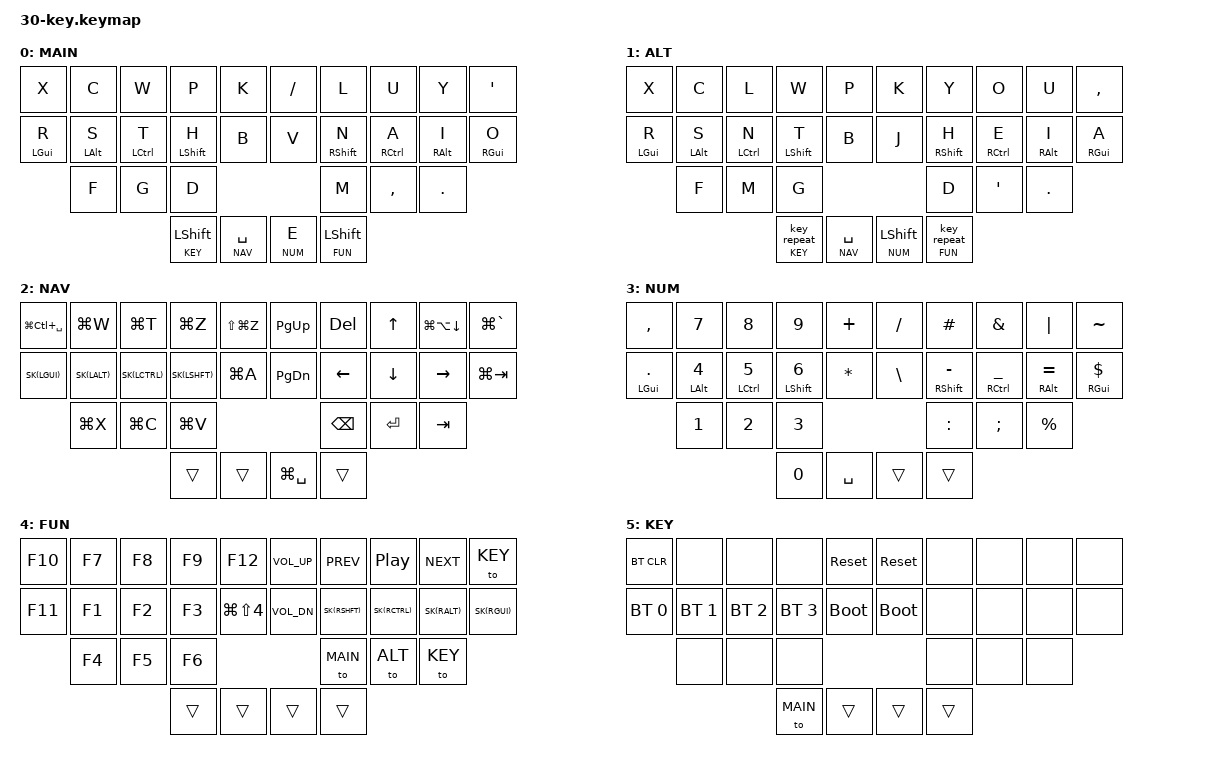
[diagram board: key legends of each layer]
#include <behaviors.dtsi>
#include <dt-bindings/zmk/keys.h>
#include <dt-bindings/zmk/bt.h>
#include <dt-bindings/zmk/outputs.h>


// Layer aliases
#define MAIN  0
#define ALT   1
#define NAV   2
#define NUM   3
#define FUN   4
#define KEY   5

// Desktop and tab navigation shortcuts
#define SS_TARGETED &kp LG(LS(N4))
#define SS_FULL     &kp LG(LS(N3))
#define WIN_LEFT    &kp LA(LC(LEFT))
#define WIN_RIGHT   &kp LA(LC(RIGHT))
#define WIN_FULL    &kp LA(LC(RET))
#define SELECT_ALL  &kp LG(A)
#define NEW_TAB     &kp LG(T)
#define FIND        &kp LG(F)
#define COMMAND     &kp LG(K)
#define U_UNDO      &kp LG(Z)
#define U_REDO      &kp LS(LG(Z))
#define U_PST       &kp LG(V)
#define U_CPY       &kp LG(C)
#define U_CUT       &kp LG(X)
#define QUIT        &kp LG(Q)
#define CLOSE       &kp LG(W)
#define APP_SWAP    &kp LG(TAB)
#define WIN_SWAP    &kp LG(GRAVE)
#define ALFRED      &kp LG(SPC)

#define HOMEROW     &kp LG(LC(SPC))
#define DUPLICATE   &kp LG(D)
#define CLIP   &kp LG(LA(DOWN))

#define SK(KEY) &nk KEY KEY

/* Key Position Groups */
#define KEYS_L 0 1 2 3 4 10 11 12 13 14 20 21 22  // left-hand keys
#define KEYS_R 5 6 7 8 9 15 16 17 18 19 23 24 25  // right-hand keys
#define THUMBS 26 27 28 29                        // thumb keys

/* Behavior Settings */
&sl {
  release-after-ms = <250>;
};

&sk {
  release-after-ms = <60000>;
  quick-release;
};

&caps_word {
    continue-list = <BACKSPACE UNDERSCORE MINUS N1 N2 N3 N4 N5 N6 N7 N8 N9 N0>;
};

&lt {
 tapping-term-ms = <175>;
 flavor = "balanced";
};

&mt {
 tapping-term-ms = <175>;
 flavor = "tap-preferred";
};

// / {
//     conditional_layers {
//         compatible = "zmk,conditional-layers";
//         tri_layer {
//             if-layers = <3 4>;
//             then-layer = <5>;
//         };
//     };
// };

#include "30-key-combos.dtsi"

/ { 
    macros {
        codeblock: codeblock {
            compatible = "zmk,behavior-macro";
            #binding-cells = <0>;
            wait-ms = <0>;
            tap-ms = <0>;
            bindings = <&macro_tap &kp GRAVE &kp GRAVE &kp GRAVE>;
        };

        func: func {
            compatible = "zmk,behavior-macro";
            #binding-cells = <0>;
            wait-ms = <0>;
            tap-ms = <0>;
            bindings = <&macro_tap &kp EQUAL &kp GT>;
        };

        you: you {
            compatible = "zmk,behavior-macro";
            #binding-cells = <0>;
            wait-ms = <0>;
            tap-ms = <0>;
            bindings = <&macro_tap &kp Y &kp O &kp U>;
        };

        dbrkl: dbrkl {
            compatible = "zmk,behavior-macro";
            #binding-cells = <0>;
            wait-ms = <0>;
            tap-ms = <0>;
            bindings = <&macro_tap &kp LBKT  &kp LBKT>;
        };

        dbrkr: dbrkr {
            compatible = "zmk,behavior-macro";
            #binding-cells = <0>;
            wait-ms = <0>;
            tap-ms = <0>;
            bindings = <&macro_tap &kp RBKT  &kp RBKT>;
        };

        yeah: yeah {
            compatible = "zmk,behavior-macro";
            #binding-cells = <0>;
            wait-ms = <0>;
            tap-ms = <0>;
            bindings = <&macro_tap &kp Y &kp E &kp A &kp H>;
        };

        mo_nav: mo_nav {
            compatible = "zmk,behavior-macro";
            #binding-cells = <0>;
            wait-ms = <0>;
            tap-ms = <0>;
            bindings
                = <&macro_tap &kp K_CANCEL>
                , <&macro_press &mo NAV>
                , <&macro_pause_for_release>
                , <&macro_release &mo NAV>;
        };
    };

    behaviors {
          hml: home-row-left {
            compatible = "zmk,behavior-hold-tap";
            label = "HOME_ROW_LEFT";
            #binding-cells = <2>;
            flavor = "balanced";
            tapping-term-ms = <280>;
            quick-tap-ms = <175>;                // double tapping same key allows for repeating
            require-prior-idle-ms = <60>;
            bindings = <&kp>, <&kp>;
            hold-trigger-key-positions = <KEYS_R THUMBS>;
            hold-trigger-on-release;
        };

        hmr: home-row-right {
            compatible = "zmk,behavior-hold-tap";
            label = "HOME_ROW_RIGHT";
            #binding-cells = <2>;
            flavor = "balanced";
            tapping-term-ms = <280>;
            quick-tap-ms = <175>;                // double tapping same key allows for repeating
            require-prior-idle-ms = <60>;
            bindings = <&kp>, <&kp>;
            hold-trigger-key-positions = <KEYS_L THUMBS>;
            hold-trigger-on-release;             // requires PR #1423
        };

        as: alpha_shift {
            compatible = "zmk,behavior-hold-tap";
            label = "ALPHA_SFT";
            #binding-cells = <2>;
            tapping-term-ms = <170>;
            quick-tap-ms = <100>;
            flavor = "tap-preferred";
            bindings = <&kp>, <&kp>;
        };

        // Sticky key on tap, normal key on hold
        // Useful for modifier-clicking without the modifier remaining active
        nk: not_so_sticky_key {
            compatible = "zmk,behavior-hold-tap";
            label = "NOT_SO_STICKY_KEY";
            #binding-cells = <2>;
            tapping_term_ms = <200>;
            flavor = "tap-preferred";
            bindings = <&kp>, <&sk>;
        };

        lst: layer_sticky_tap {
            compatible = "zmk,behavior-hold-tap";
            label = "LAYER_STICKY_TAP";
            #binding-cells = <2>;
            tapping-term-ms = <200>;
            quick_tap_ms = <0>;
            flavor = "tap-preferred";
            bindings = <&mo>, <&sk>;
        };

        lr: layer_repeat {
            compatible = "zmk,behavior-hold-tap";
            label = "LAYER_REPEAT";
            #binding-cells = <2>;
            tapping_term_ms = <200>;
            quick-tap-ms = <175>;
            flavor = "balanced";
            bindings = <&mo>, <&key_repeat>;
        };

        lc: layer_caps {
            compatible = "zmk,behavior-hold-tap";
            label = "LAYER_CAPS";
            #binding-cells = <2>;
            tapping_term_ms = <200>;
            quick-tap-ms = <175>;
            flavor = "balanced";
            bindings = <&mo>, <&caps_word>;
        };

        dotexcl: dot_excl {
            compatible = "zmk,behavior-mod-morph";
            label = "DOT_EXCL";
            #binding-cells = <0>;
            bindings = <&kp DOT>, <&kp EXCL>;
            mods = <(MOD_LSFT|MOD_RSFT)>;
        };
    };

    keymap {
        compatible = "zmk,keymap";
// x c w p k  j l u y '
// r s t h b  v n a i o
//  f g d      m , .
//        _  e
// 
// 
   
 
 main_layer {
            label = "MAIN";
            bindings = <
// ╭─────────────┬─────────────┬─────────────┬─────────────┬─────────────╮   ╭─────────────┬─────────────┬─────────────┬─────────────┬─────────────╮
     &kp X        &kp C         &kp W         &kp P         &kp K             &kp SLASH         &kp L         &kp U         &kp Y         &kp SQT
// ├────────────┼─────────────┼─────────────┼─────────────┼─────────────┤    ├─────────────┼─────────────┼─────────────┼─────────────┼─────────────┤
     &hml LGUI R   &hml LALT S   &hml LCTRL T  &hml LSHFT H  &kp B             &kp V         &hmr RSHFT N  &hmr RCTRL A  &hmr RALT I   &hmr RGUI O     
// ├─────────────┼─────────────┼─────────────┼─────────────┼─────────────┤   ├─────────────┼─────────────┼─────────────┼─────────────┼─────────────┤
                   &kp F         &kp G         &kp D                                         &kp M         &kp COMMA     &kp DOT
// ╰─────────────┴─────────────┴─────────────┼─────────────┼─────────────┤   ├─────────────┼─────────────┼─────────────┴─────────────┴─────────────╯
                                               &lst KEY LSHFT  &lt NAV SPACE     &lt NUM E     &lst FUN LSHFT
//                             ╰─────────────┴─────────────┴─────────────╯   ╰─────────────┴─────────────┴─────────────╯
        >;
    };

// ONE
// x c y d k  / l o u '     x c y d k j l o u ' 
// r s t h b  w n e i a      r s t h b w n e i a 
//   f g p      m , .         f g p v z q m , . 

// TWO
// x c d l k  p y o u '     x c d l k j y o u '
// r s t h v  w n e i a      r s t h v p n e i a 
//   g b m      f , .         g b m q z w f , . 

// THREE
// x c l d k  / y o u '     x c l d k j y o u '
// r s h t b  p n e i a      r s h t v p n e i a 
//   g m w      f , .         g m w b z q f , . 

// FOUR
// v c l d k  x y o u '     v c l d q j y o u '
// r s n t b  p h e i a      r s n t k p h e i a
//   w m g      f , .         w m g b z x f , .

// FIVE
// w c l d g  j u o y k     w c l d v  j u o y '
// r s n t b  / a e i h      r s n t g  p a e i h k
//   f m p      x , .         f m p b z  x f , .

// x c g d k         j l u y '
// r s t h p         v n a i o
//   b w f             m , . 
//                   e



     alt_layer {
             label = "ALT";
             bindings = <
 // ╭─────────────┬─────────────┬─────────────┬─────────────┬─────────────╮   ╭─────────────┬─────────────┬─────────────┬─────────────┬─────────────╮
      &kp X         &kp C         &kp L         &kp W         &kp P             &kp K         &kp Y         &kp O         &kp U         &kp COMMA
 // ├────────────┼─────────────┼─────────────┼─────────────┼─────────────┤    ├─────────────┼─────────────┼─────────────┼─────────────┼─────────────┤
      &hml LGUI R   &hml LALT S   &hml LCTRL N  &hml LSHFT T  &kp B             &kp J         &hmr RSHFT H  &hmr RCTRL E  &hmr RALT I   &hmr RGUI A     
 // ├─────────────┼─────────────┼─────────────┼─────────────┼─────────────┤   ├─────────────┼─────────────┼─────────────┼─────────────┼─────────────┤
                    &kp F         &kp M         &kp G                                         &kp D         &kp SQT     &kp DOT
 // ╰─────────────┴─────────────┴─────────────┼─────────────┼─────────────┤   ├─────────────┼─────────────┼─────────────┴─────────────┴─────────────╯
                                                &lr KEY 0     &lt NAV SPACE     &lst NUM LSHFT  &lr FUN 0 
 //                             ╰─────────────┴─────────────┴─────────────╯   ╰─────────────┴─────────────┴─────────────╯
         >;
     };

    nav_layer {
            label = "NAV";
            bindings = <
// ╭─────────────┬─────────────┬─────────────┬─────────────┬─────────────╮   ╭─────────────┬─────────────┬─────────────┬─────────────┬─────────────╮
     HOMEROW       CLOSE         NEW_TAB       U_UNDO        U_REDO            &kp PG_UP     &kp DEL       &kp UP        CLIP          WIN_SWAP
// ├─────────────┼─────────────┼─────────────┼─────────────┼─────────────┤   ├─────────────┼─────────────┼─────────────┼─────────────┼────────────┤
     SK(LGUI)      SK(LALT)      SK(LCTRL)     SK(LSHFT)     SELECT_ALL        &kp PG_DN     &kp LEFT      &kp DOWN      &kp RIGHT     APP_SWAP        
// ├─────────────┼─────────────┼─────────────┼─────────────┼─────────────┤   ├─────────────┼─────────────┼─────────────┼─────────────┼─────────────┤
                   U_CUT         U_CPY         U_PST                                         &kp BSPC      &kp RET       &kp TAB                           
// ╰─────────────┴─────────────┴─────────────┼─────────────┼─────────────┤   ├─────────────┼─────────────┼─────────────┴─────────────┴─────────────╯
                                               &trans        &trans            ALFRED        &trans
//                             ╰─────────────┴─────────────┴─────────────╯   ╰─────────────┴─────────────┴─────────────╯
            >;
        };

        num_layer { 
            label = "NUM"; 
            bindings = <
// ╭─────────────┬─────────────┬─────────────┬─────────────┬─────────────╮   ╭─────────────┬─────────────┬─────────────┬─────────────┬─────────────╮
     &kp COMMA      &kp N7        &kp N8       &kp N9        &kp PLUS          &kp SLASH      &kp HASH      &kp AMPS      &kp PIPE      &kp TILDE
// ├─────────────┼─────────────┼─────────────┼─────────────┼ ────────────┤   ├──────────────┼─────────────┼─────────────┼─────────────┼─────────────┤
     &hml LGUI DOT  &hml LALT N4  &hml LCTRL N5 &hml LSHFT N6 &kp STAR         &kp BSLH     &hmr RSHFT MINUS &hmr RCTRL UNDER &hmr RALT EQUAL &hmr RGUI DOLLAR
// ├─────────────┼─────────────┼─────────────┼─────────────┼─────────────┤   ├─────────────┼─────────────┼─────────────┼─────────────┼─────────────┤
                    &kp N1        &kp N2       &kp N3                                        &kp COLON     &kp SEMI      &kp PERCENT                 
// ╰─────────────┴─────────────┴─────────────┼─────────────┼─────────────┤   ├─────────────┼─────────────┼─────────────┴─────────────┴─────────────╯
                                                &kp N0       &kp SPACE         &trans        &trans
//                             ╰─────────────┴─────────────┴─────────────╯   ╰─────────────┴─────────────┴─────────────╯
            >;
        };

        function_layer { 
            label = "FUN";
            bindings = <
// ╭─────────────┬─────────────┬─────────────┬─────────────┬─────────────╮   ╭─────────────┬─────────────┬─────────────┬─────────────┬─────────────╮
     &kp F10       &kp F7        &kp F8        &kp F9        &kp F12           &kp C_VOL_UP  &kp C_PREV    &kp C_PP      &kp C_NEXT    &to KEY
// ├─────────────┼───────────┼─────────────┼───────────────┼─────────────┤   ├─────────────┼─────────────┼─────────────┼─────────────┼─────────────┤
     &kp F11       &kp F1        &kp F2        &kp F3        SS_TARGETED       &kp C_VOL_DN  SK(RSHFT)     SK(RCTRL)     SK(RALT)      SK(RGUI)
// ├─────────────┼───────────┼─────────────┼───────────────┼─────────────┤   ├─────────────┼─────────────┼─────────────┼─────────────┼─────────────┤
                   &kp F4        &kp F5        &kp F6                                        &to MAIN      &to ALT       &to KEY                     
// ├─────────────┼─────────────┼─────────────┴─────────────┴─────────────╯   ├─────────────┼─────────────┼─────────────┴─────────────┴─────────────╯
                                               &trans        &trans            &trans        &trans             
//                             ╰─────────────┴─────────────┴─────────────╯   ╰─────────────┴─────────────┴─────────────╯
            >;
        };

        keyboard_layer {
            label = "KEY";
            bindings = <
// ╭─────────────┬─────────────┬─────────────┬─────────────┬─────────────╮   ╭─────────────┬─────────────┬─────────────┬─────────────┬─────────────╮
     &bt BT_CLR    &none         &none         &none         &sys_reset         &sys_reset    &none        &none        &none        &none
// ├─────────────┼─────────────┼─────────────┼─────────────┼─────────────┤   ├─────────────┼───────────┼─────────────┼───────────────┼─────────────┤
     &bt BT_SEL 0  &bt BT_SEL 1  &bt BT_SEL 2  &bt BT_SEL 3  &bootloader        &bootloader   &none        &none        &none        &none
// ├─────────────┼─────────────┼─────────────┼─────────────┼─────────────┤   ├─────────────┼───────────┼─────────────┼───────────────┼─────────────┤
                   &none         &none         &none                                          &none        &none        &none                     
// ├─────────────┼─────────────┼─────────────┴─────────────┴─────────────╯   ├─────────────┼─────────────┼─────────────┴─────────────┴─────────────╯
                                               &to MAIN      &trans             &trans        &trans
//                             ╰─────────────┴─────────────┴─────────────╯   ╰─────────────┴─────────────┴─────────────╯
            >;
        };
    };
};
